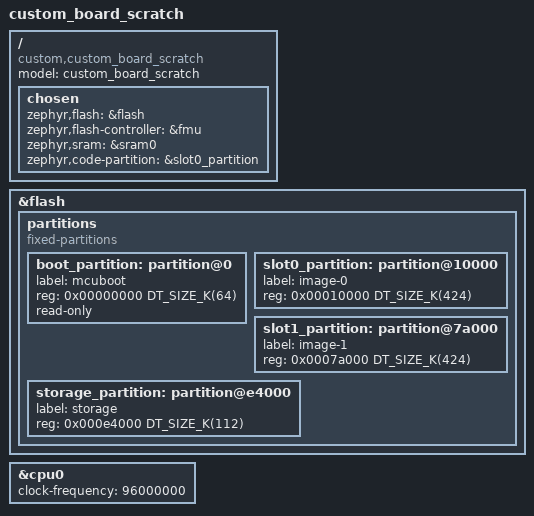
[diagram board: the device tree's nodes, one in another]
/dts-v1/;
#include <nxp/mcx/mcxa/nxp_mcxa156.dtsi>
#include "custom_board_scratch-pinctrl.dtsi"
#include <zephyr/dt-bindings/input/input-event-codes.h>
/ {
    model = "custom_board_scratch";
    compatible = "custom,custom_board_scratch";
    chosen {
        zephyr,flash = &flash;
        zephyr,flash-controller = &fmu;
        zephyr,sram = &sram0; /* Point to regular RAM */
        zephyr,code-partition = &slot0_partition; /* Regular application slot */
    };
};

&flash {
	partitions {
		compatible = "fixed-partitions";
		#address-cells = <1>;
		#size-cells = <1>;

		boot_partition: partition@0 {
			label = "mcuboot";
			reg = <0x00000000 DT_SIZE_K(64)>;
			read-only;
		};

		slot0_partition: partition@10000 {
			label = "image-0";
			reg = <0x00010000 DT_SIZE_K(424)>;
		};

		slot1_partition: partition@7a000 {
			label = "image-1";
			reg = <0x0007a000 DT_SIZE_K(424)>;
		};

		storage_partition: partition@e4000 {
			label = "storage";
			reg = <0x000e4000 DT_SIZE_K(112)>;
		};
	};
};

&cpu0 {
	clock-frequency = <96000000>;
};
